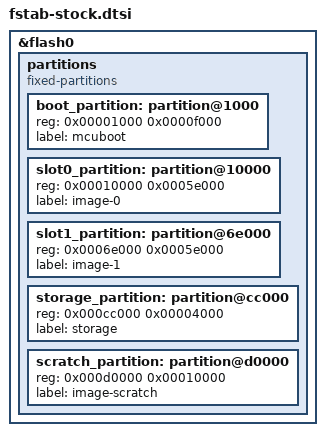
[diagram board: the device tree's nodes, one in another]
/*
 * Copyright (c) 2019 Nordic Semiconductor ASA
 *
 * SPDX-License-Identifier: Apache-2.0
 */

/* Flash partition table compatible with Nordic nRF5 bootloader */

&flash0 {
	partitions {
		compatible = "fixed-partitions";
		#address-cells = <1>;
		#size-cells = <1>;

		/* MCUboot placed after Nordic MBR.
		 * The size of this partition ensures that MCUBoot
		 * can be built with CDC ACM support and w/o optimizations.
		 */
		boot_partition: partition@1000 {
			reg = <0x00001000 0x0000f000>;
			label = "mcuboot";
		};

		slot0_partition: partition@10000 {
			reg = <0x00010000 0x0005e000>;
			label = "image-0";
		};

		slot1_partition: partition@6e000 {
			reg = <0x0006e000 0x0005e000>;
			label = "image-1";
		};

		storage_partition: partition@cc000 {
			reg = <0x000cc000 0x00004000>;
			label = "storage";
		};

		scratch_partition: partition@d0000 {
			reg = <0x000d0000 0x00010000>;
			label = "image-scratch";
		};

		/* Nordic nRF5 bootloader <0xe0000 0x1c000>
		 *
		 * In addition, the last and second last flash pages
		 * are used by the nRF5 bootloader and MBR to store settings.
		 */
	};
};
